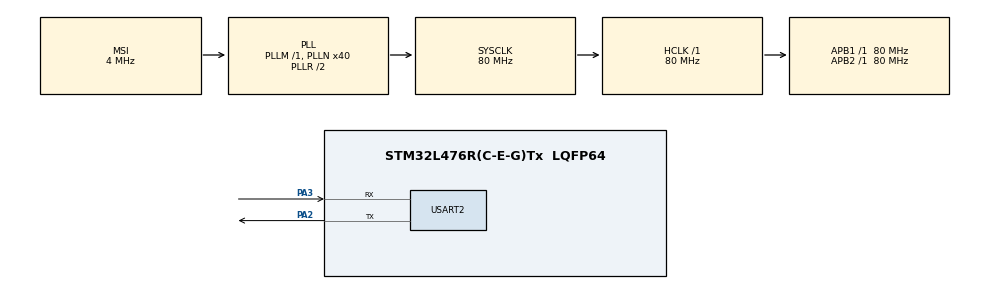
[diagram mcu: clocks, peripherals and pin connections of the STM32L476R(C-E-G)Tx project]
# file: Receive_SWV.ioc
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Mcu.Family=STM32L4
Mcu.Name=STM32L476R(C-E-G)Tx
Mcu.Package=LQFP64
NVIC.PriorityGroup=NVIC_PRIORITYGROUP_4
NVIC.USART2_IRQn=true\:0\:0\:false\:false\:true\:true\:true\:true
PA13\ (JTMS-SWDIO).Mode=Serial_Wire
PA13\ (JTMS-SWDIO).Signal=SYS_JTMS-SWDIO
PA14\ (JTCK-SWCLK).Mode=Serial_Wire
PA14\ (JTCK-SWCLK).Signal=SYS_JTCK-SWCLK
PA2.Mode=Asynchronous
PA2.Signal=USART2_TX
PA3.Mode=Asynchronous
PA3.Signal=USART2_RX
PH0-OSC_IN\ (PH0).Mode=HSE-External-Oscillator
PH0-OSC_IN\ (PH0).Signal=RCC_OSC_IN
PH1-OSC_OUT\ (PH1).Mode=HSE-External-Oscillator
PH1-OSC_OUT\ (PH1).Signal=RCC_OSC_OUT
ProjectManager.HeapSize=0x200
ProjectManager.StackSize=0x400
ProjectManager.TargetToolchain=STM32CubeIDE
RCC.AHBFreq_Value=80000000
RCC.APB1Freq_Value=80000000
RCC.APB1TimFreq_Value=80000000
RCC.APB2Freq_Value=80000000
RCC.APB2TimFreq_Value=80000000
RCC.CortexFreq_Value=80000000
RCC.HCLKFreq_Value=80000000
RCC.HSE_VALUE=8000000
RCC.HSI_VALUE=16000000
RCC.LSE_VALUE=32768
RCC.MSI_VALUE=4000000
RCC.PLLN=40
RCC.SYSCLKFreq_VALUE=80000000
RCC.SYSCLKSource=RCC_SYSCLKSOURCE_PLLCLK
RCC.VCOOutputFreq_Value=160000000
USART2.VirtualMode-Asynchronous=VM_ASYNC
board=custom

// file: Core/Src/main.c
/* USER CODE BEGIN Header */
/**
  ******************************************************************************
  * @file           : main.c
  * @brief          : Main program body
  ******************************************************************************
  * @attention
  *
  * Copyright (c) 2025 STMicroelectronics.
  * All rights reserved.
  *
  * This software is licensed under terms that can be found in the LICENSE file
  * in the root directory of this software component.
  * If no LICENSE file comes with this software, it is provided AS-IS.
  *
  ******************************************************************************
  */
/* USER CODE END Header */
#include "main.h"
#include "string.h"

UART_HandleTypeDef huart2;

/* USER CODE BEGIN PV */
uint8_t RxData[8];              // Buffer for current received data (8 bytes)
uint8_t Storage[50];            // Buffer to store previous data (50 bytes)
volatile uint8_t RxDataIndex = 0;    // Index for RxData
volatile uint8_t StorageIndex = 0;   // Index for Storage
volatile uint8_t RxByte;        // Temporary variable for received byte
/* USER CODE END PV */

void SystemClock_Config(void);
static void MX_GPIO_Init(void);
static void MX_USART2_UART_Init(void);
/* USER CODE BEGIN PFP */
void AppendToStorage(uint8_t byte);
int _write(int file, char *ptr, int len);  // Add this for ITM printf
/* USER CODE END PFP */

/* USER CODE BEGIN 0 */
int _write(int file, char *ptr, int len)
{
    for (int i = 0; i < len; i++)
    {
        ITM_SendChar(ptr[i]);
    }
    return len;
}
void HAL_UART_RxCpltCallback(UART_HandleTypeDef *huart)
{
    if (huart->Instance == USART2)  // Check if interrupt is from USART2
    {
        // Store byte in RxData, wrap around if index exceeds 7
        RxData[RxDataIndex] = RxByte;
        RxDataIndex = (RxDataIndex + 1) % 8;  // Wrap around: 0 to 7

        // Append the byte to Storage
        AppendToStorage(RxByte);

        // Print to SWV console
        printf("Rx: %c\n", RxByte); // Modified to include a label and newline

        // Restart UART interrupt for next byte
        HAL_UART_Receive_IT(&huart2, (uint8_t*)&RxByte, 1);
    }
}
/* Append a single byte to Storage, reset Storage if full */
void AppendToStorage(uint8_t byte)
{
  // Check if Storage is full
  if (StorageIndex >= 50)
  {
    // Reset Storage and start over
    memset(Storage, 0, sizeof(Storage));
    StorageIndex = 0;
  }

  // Append the byte to Storage
  Storage[StorageIndex++] = byte;
}
/* USER CODE END 0 */

int main(void)
{

  /* MCU Configuration--------------------------------------------------------*/

  /* Reset of all peripherals, Initializes the Flash interface and the Systick. */
  HAL_Init();

  /* Configure the system clock */
  SystemClock_Config();

  /* Initialize all configured peripherals */
  MX_GPIO_Init();
  MX_USART2_UART_Init();
  /* USER CODE BEGIN 2 */
  memset(RxData, 0, sizeof(RxData));
    memset(Storage, 0, sizeof(Storage));
    RxDataIndex = 0;
    StorageIndex = 0;
    HAL_UART_Receive_IT(&huart2, (uint8_t*)&RxByte, 1);
    printf("SWV Test Message\n"); // Test SWV output
    /* USER CODE END 2 */  /* USER CODE END 2 */

  /* Infinite loop */
  while (1)
  {
  }
  /* USER CODE END 3 */
}

void SystemClock_Config(void)
{
  RCC_OscInitTypeDef RCC_OscInitStruct = {0};
  RCC_ClkInitTypeDef RCC_ClkInitStruct = {0};

  /** Configure the main internal regulator output voltage
  */
  if (HAL_PWREx_ControlVoltageScaling(PWR_REGULATOR_VOLTAGE_SCALE1) != HAL_OK)
  {
    Error_Handler();
  }

  /** Initializes the RCC Oscillators according to the specified parameters
  * in the RCC_OscInitTypeDef structure.
  */
  RCC_OscInitStruct.OscillatorType = RCC_OSCILLATORTYPE_MSI;
  RCC_OscInitStruct.MSIState = RCC_MSI_ON;
  RCC_OscInitStruct.MSICalibrationValue = 0;
  RCC_OscInitStruct.MSIClockRange = RCC_MSIRANGE_6;
  RCC_OscInitStruct.PLL.PLLState = RCC_PLL_ON;
  RCC_OscInitStruct.PLL.PLLSource = RCC_PLLSOURCE_MSI;
  RCC_OscInitStruct.PLL.PLLM = 1;
  RCC_OscInitStruct.PLL.PLLN = 40;
  RCC_OscInitStruct.PLL.PLLP = RCC_PLLP_DIV7;
  RCC_OscInitStruct.PLL.PLLQ = RCC_PLLQ_DIV2;
  RCC_OscInitStruct.PLL.PLLR = RCC_PLLR_DIV2;
  if (HAL_RCC_OscConfig(&RCC_OscInitStruct) != HAL_OK)
  {
    Error_Handler();
  }

  /** Initializes the CPU, AHB and APB buses clocks
  */
  RCC_ClkInitStruct.ClockType = RCC_CLOCKTYPE_HCLK|RCC_CLOCKTYPE_SYSCLK
                              |RCC_CLOCKTYPE_PCLK1|RCC_CLOCKTYPE_PCLK2;
  RCC_ClkInitStruct.SYSCLKSource = RCC_SYSCLKSOURCE_PLLCLK;
  RCC_ClkInitStruct.AHBCLKDivider = RCC_SYSCLK_DIV1;
  RCC_ClkInitStruct.APB1CLKDivider = RCC_HCLK_DIV1;
  RCC_ClkInitStruct.APB2CLKDivider = RCC_HCLK_DIV1;

  if (HAL_RCC_ClockConfig(&RCC_ClkInitStruct, FLASH_LATENCY_4) != HAL_OK)
  {
    Error_Handler();
  }
}

static void MX_USART2_UART_Init(void)
{

  huart2.Instance = USART2;
  huart2.Init.BaudRate = 115200;
  huart2.Init.WordLength = UART_WORDLENGTH_8B;
  huart2.Init.StopBits = UART_STOPBITS_1;
  huart2.Init.Parity = UART_PARITY_NONE;
  huart2.Init.Mode = UART_MODE_TX_RX;
  huart2.Init.HwFlowCtl = UART_HWCONTROL_NONE;
  huart2.Init.OverSampling = UART_OVERSAMPLING_16;
  huart2.Init.OneBitSampling = UART_ONE_BIT_SAMPLE_DISABLE;
  huart2.AdvancedInit.AdvFeatureInit = UART_ADVFEATURE_NO_INIT;
  if (HAL_UART_Init(&huart2) != HAL_OK)
  {
    Error_Handler();
  }

}

static void MX_GPIO_Init(void)
{

  /* GPIO Ports Clock Enable */
  __HAL_RCC_GPIOH_CLK_ENABLE();
  __HAL_RCC_GPIOA_CLK_ENABLE();

}

void Error_Handler(void)
{
  __disable_irq();
  while (1)
  {
  }
}
